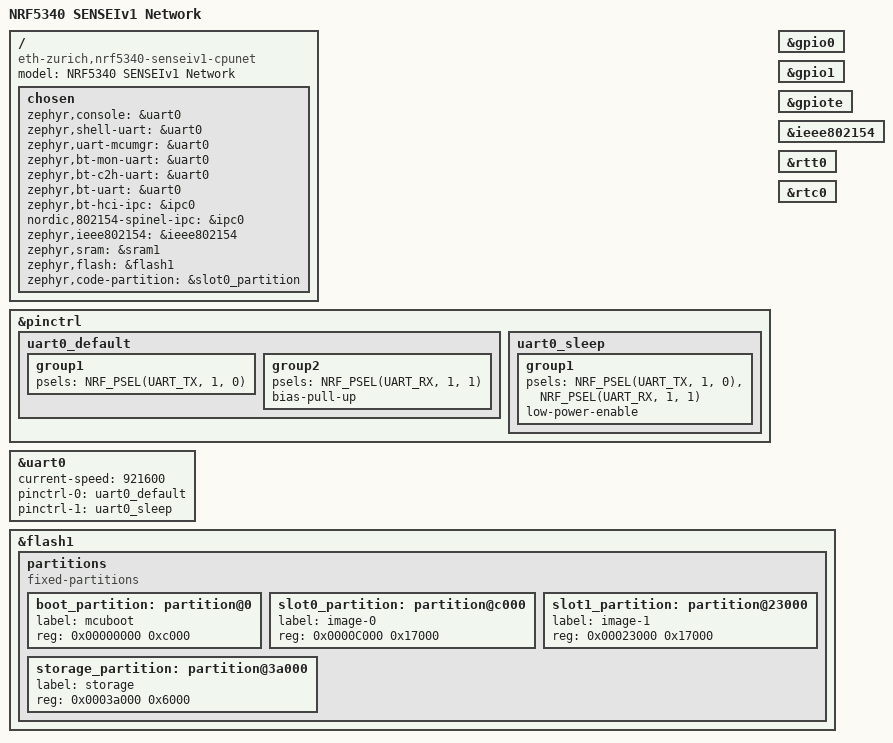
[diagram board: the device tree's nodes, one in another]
// Copyright (c) 2025 ETH Zurich and University of Bologna
// SPDX-License-Identifier: Apache-2.0

/dts-v1/;
#include <nordic/nrf5340_cpunet_qkaa.dtsi>
#include <zephyr/dt-bindings/input/input-event-codes.h>

/ {
	model = "NRF5340 SENSEIv1 Network";
	compatible = "eth-zurich,nrf5340-senseiv1-cpunet";

	chosen {
		zephyr,console = &uart0;
		zephyr,shell-uart = &uart0;
		zephyr,uart-mcumgr = &uart0;
		zephyr,bt-mon-uart = &uart0;
		zephyr,bt-c2h-uart = &uart0;
		zephyr,bt-uart = &uart0;
		zephyr,bt-hci-ipc = &ipc0;
		nordic,802154-spinel-ipc = &ipc0;
		zephyr,ieee802154 = &ieee802154;
		zephyr,sram = &sram1;
		zephyr,flash = &flash1;
		zephyr,code-partition = &slot0_partition;
	};
};

#include "nrf5340_senseiv1_shared.dtsi"

&pinctrl {
	uart0_default: uart0_default {
		group1 {
			psels = <NRF_PSEL(UART_TX, 1, 0)>;
		};
		group2 {
			psels = <NRF_PSEL(UART_RX, 1, 1)>;
			bias-pull-up;
		};
	};

	uart0_sleep: uart0_sleep {
		group1 {
			psels = <NRF_PSEL(UART_TX, 1, 0)>,
				<NRF_PSEL(UART_RX, 1, 1)>;
			low-power-enable;
		};
	};
};


&uart0 {
	status = "okay";
	current-speed = <921600>;
	pinctrl-0 = <&uart0_default>;
	pinctrl-1 = <&uart0_sleep>;
	pinctrl-names = "default", "sleep";
};


&gpio0 {
	status = "okay";
};

&gpio1 {
	status = "okay";
};

&gpiote {
	status = "okay";
};

&ieee802154 {
	status = "okay";
};

&rtt0 {
    status = "okay";
};

&rtc0 {
	status = "okay";
};


&flash1 {

	partitions {
		compatible = "fixed-partitions";
		#address-cells = <1>;
		#size-cells = <1>;

		boot_partition: partition@0 {
			label = "mcuboot";
			reg = <0x00000000 0xc000>;
		};
		slot0_partition: partition@c000 {
			label = "image-0";
			reg = <0x0000C000 0x17000>;
		};
		slot1_partition: partition@23000 {
			label = "image-1";
			reg = <0x00023000 0x17000>;
		};
		storage_partition: partition@3a000 {
			label = "storage";
			reg = <0x0003a000 0x6000>;
		};
	};
};

